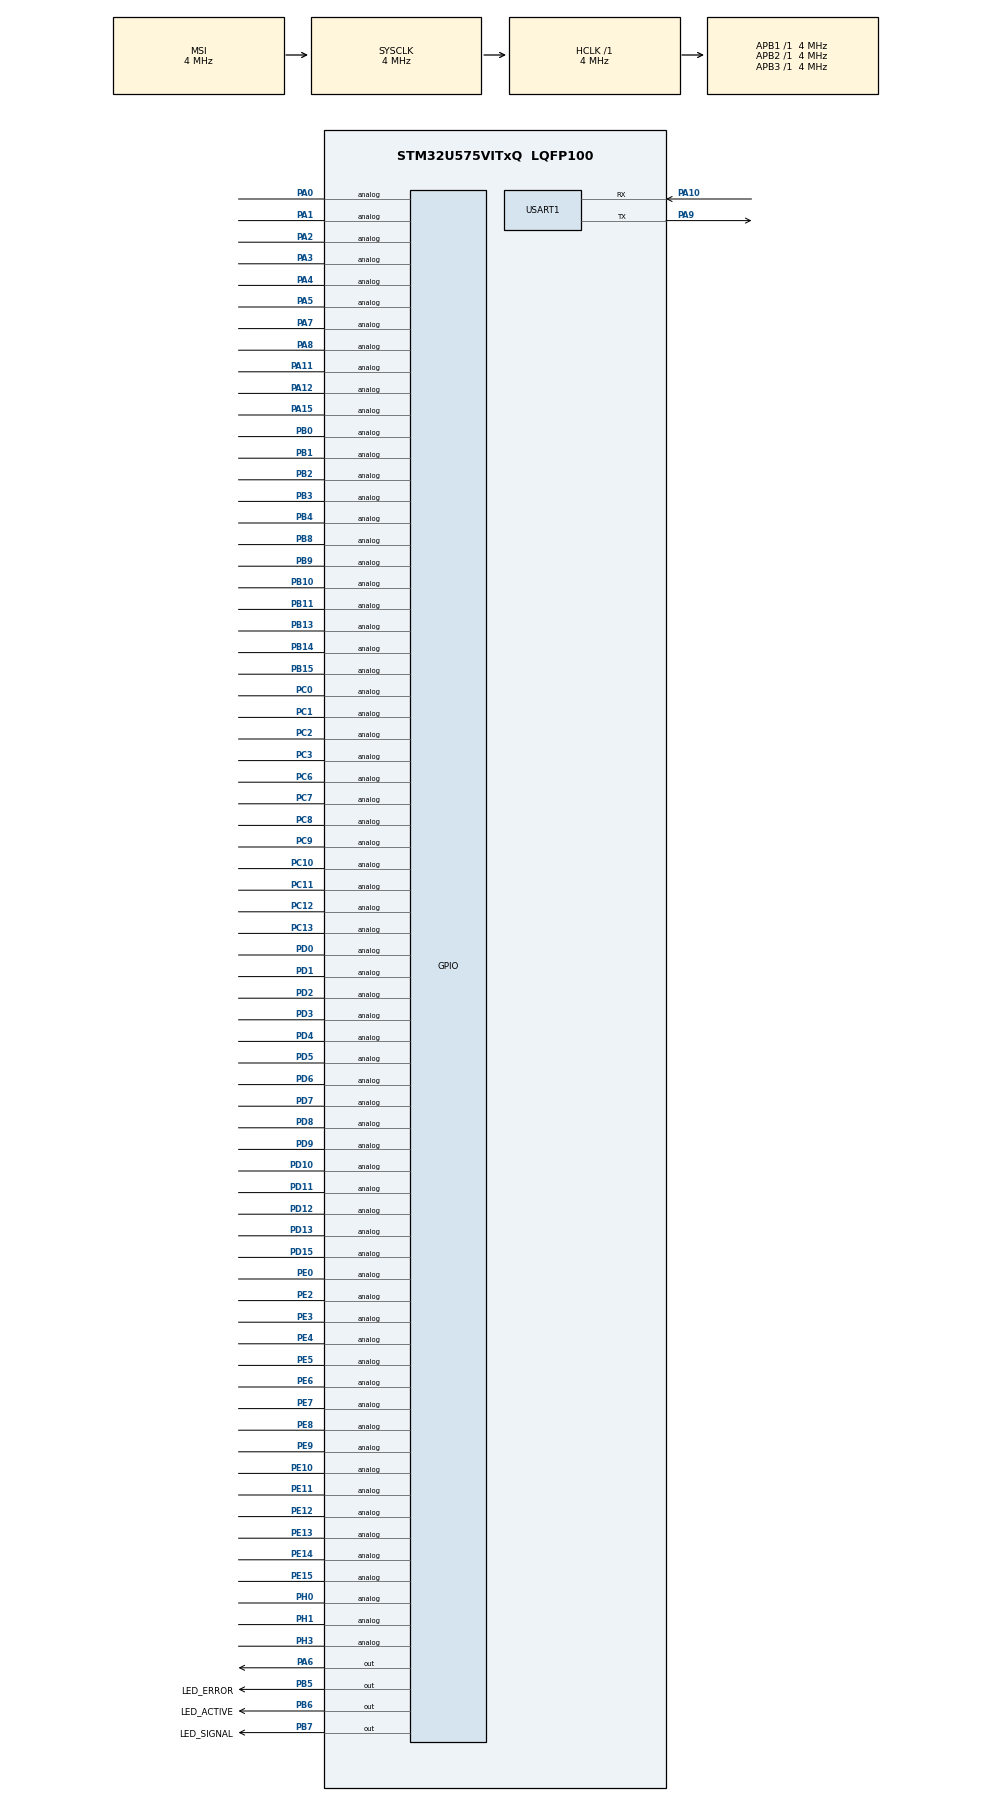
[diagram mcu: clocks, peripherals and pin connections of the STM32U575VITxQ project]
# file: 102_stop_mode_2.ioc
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CORTEX_M33_NS.userName=CORTEX_M33
Mcu.Family=STM32U5
Mcu.Name=STM32U575VITxQ
Mcu.Package=LQFP100
NVIC.PriorityGroup=NVIC_PRIORITYGROUP_4
NVIC.RTC_IRQn=true\:0\:0\:false\:false\:true\:true\:true\:true
PA0.Signal=GPIO_Analog
PA1.Signal=GPIO_Analog
PA10.Mode=Asynchronous
PA10.Signal=USART1_RX
PA11.Signal=GPIO_Analog
PA12.Signal=GPIO_Analog
PA13\ (JTMS/SWDIO).Mode=Serial_Wire
PA13\ (JTMS/SWDIO).Signal=DEBUG_JTMS-SWDIO
PA14\ (JTCK/SWCLK).Mode=Serial_Wire
PA14\ (JTCK/SWCLK).Signal=DEBUG_JTCK-SWCLK
PA15\ (JTDI).Signal=GPIO_Analog
PA2.Signal=GPIO_Analog
PA3.Signal=GPIO_Analog
PA4.Signal=GPIO_Analog
PA5.Signal=GPIO_Analog
PA6.Signal=GPIO_Output
PA7.Signal=GPIO_Analog
PA8.Signal=GPIO_Analog
PA9.Mode=Asynchronous
PA9.Signal=USART1_TX
PB0.Signal=GPIO_Analog
PB1.Signal=GPIO_Analog
PB10.Signal=GPIO_Analog
PB11.Signal=GPIO_Analog
PB13.Signal=GPIO_Analog
PB14.Signal=GPIO_Analog
PB15.Signal=GPIO_Analog
PB2.Signal=GPIO_Analog
PB3\ (JTDO/TRACESWO).Signal=GPIO_Analog
PB4\ (NJTRST).Signal=GPIO_Analog
PB5.GPIO_Label=LED_ERROR
PB5.Signal=GPIO_Output
PB6.GPIO_Label=LED_ACTIVE
PB6.Signal=GPIO_Output
PB7.GPIO_Label=LED_SIGNAL
PB7.Signal=GPIO_Output
PB8.Signal=GPIO_Analog
PB9.Signal=GPIO_Analog
PC0.Signal=GPIO_Analog
PC1.Signal=GPIO_Analog
PC10.Signal=GPIO_Analog
PC11.Signal=GPIO_Analog
PC12.Signal=GPIO_Analog
PC13.Signal=GPIO_Analog
PC14-OSC32_IN\ (PC14).Mode=LSE-External-Oscillator
PC14-OSC32_IN\ (PC14).Signal=RCC_OSC32_IN
PC15-OSC32_OUT\ (PC15).Mode=LSE-External-Oscillator
PC15-OSC32_OUT\ (PC15).Signal=RCC_OSC32_OUT
PC2.Signal=GPIO_Analog
PC3.Signal=GPIO_Analog
PC6.Signal=GPIO_Analog
PC7.Signal=GPIO_Analog
PC8.Signal=GPIO_Analog
PC9.Signal=GPIO_Analog
PD0.Signal=GPIO_Analog
PD1.Signal=GPIO_Analog
PD10.Signal=GPIO_Analog
PD11.Signal=GPIO_Analog
PD12.Signal=GPIO_Analog
PD13.Signal=GPIO_Analog
PD14.Signal=S_LPTIM3_CH1
PD15.Signal=GPIO_Analog
PD2.Signal=GPIO_Analog
PD3.Signal=GPIO_Analog
PD4.Signal=GPIO_Analog
PD5.Signal=GPIO_Analog
PD6.Signal=GPIO_Analog
PD7.Signal=GPIO_Analog
PD8.Signal=GPIO_Analog
PD9.Signal=GPIO_Analog
PE0.Signal=GPIO_Analog
PE10.Signal=GPIO_Analog
PE11.Signal=GPIO_Analog
PE12.Signal=GPIO_Analog
PE13.Signal=GPIO_Analog
PE14.Signal=GPIO_Analog
PE15.Signal=GPIO_Analog
PE2.Signal=GPIO_Analog
PE3.Signal=GPIO_Analog
PE4.Signal=GPIO_Analog
PE5.Signal=GPIO_Analog
PE6.Signal=GPIO_Analog
PE7.Signal=GPIO_Analog
PE8.Signal=GPIO_Analog
PE9.Signal=GPIO_Analog
PH0-OSC_IN\ (PH0).Signal=GPIO_Analog
PH1-OSC_OUT\ (PH1).Signal=GPIO_Analog
PH3-BOOT0.Signal=GPIO_Analog
PWR.PowerMode=PWR_SMPS_SUPPLY
PWR.RAM1Page1PowerDownInStopMode=__NULL
PWR.RAM1Page2PowerDownInStopMode=__NULL
PWR.RAM1Page3PowerDownInStopMode=__NULL
PWR.RAM2Page1PowerDownInStopMode=__NULL
PWR.RAM2Page2PowerDownInStopMode=__NULL
PWR.RAM3Page1PowerDownInStopMode=__NULL
PWR.RAM3Page2PowerDownInStopMode=__NULL
PWR.RAM3Page3PowerDownInStopMode=__NULL
PWR.RAM3Page4PowerDownInStopMode=__NULL
PWR.RAM3Page5PowerDownInStopMode=__NULL
PWR.RAM3Page6PowerDownInStopMode=__NULL
PWR.RAM3Page7PowerDownInStopMode=__NULL
PWR.RAM3Page8PowerDownInStopMode=__NULL
PWR.SRAM4PowerDownInStopMode=__NULL
ProjectManager.HeapSize=0x200
ProjectManager.StackSize=0x400
ProjectManager.TargetToolchain=STM32CubeIDE
RCC.ADCFreq_Value=16000000
RCC.AHBFreq_Value=4000000
RCC.APB1Freq_Value=4000000
RCC.APB1TimFreq_Value=4000000
RCC.APB2Freq_Value=4000000
RCC.APB2TimFreq_Value=4000000
RCC.APB3Freq_Value=4000000
RCC.CortexFreq_Value=4000000
RCC.EPOD_VALUE=4000000
RCC.HCLKFreq_Value=4000000
RCC.HSE_VALUE=16000000
RCC.HSI48_VALUE=48000000
RCC.HSI_VALUE=16000000
RCC.LPTIM3CLockSelectionVirtual=RCC_LPTIM34CLKSOURCE_LSE
RCC.LSIDIV_VALUE=32000
RCC.MSI_VALUE=4000000
RCC.RTCClockSelection=RCC_RTCCLKSOURCE_LSE
RCC.SYSCLKFreq_VALUE=4000000
RCC.USBFreq_Value=48000000
RCC.VCOOutputFreq_Value=516000000
RCC.VDD_VALUE=3
RTC.WakeUpClock-WakeUp=RTC_WAKEUPCLOCK_CK_SPRE_16BITS
RTC.WakeUpCounter-WakeUp=0
SH.S_LPTIM3_CH1.0=LPTIM3_CH1
USART1.VirtualMode-Asynchronous=VM_ASYNC
VP_ICACHE_VS_ICACHE.Mode=DirectMappedCache
VP_LPBAMQUEUE_VS_QUEUE.Mode=QUEUEMODE
VP_LPBAM_VS_SIG1.Mode=SmartRun
VP_LPBAM_VS_SIG4.Mode=LPDMA1
VP_MEMORYMAP_VS_MEMORYMAP.Mode=CurAppReg
VP_PWR_VS_DBSignals.Mode=DisableDeadBatterySignals
VP_PWR_VS_LPOM.Mode=PowerOptimisation
VP_PWR_VS_SECSignals.Mode=Security/Privilege
VP_RTC_VS_RTC_Activate.Mode=RTC_Enabled
VP_RTC_VS_RTC_WakeUp_intern.Mode=WakeUp
board=custom

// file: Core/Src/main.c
/* USER CODE BEGIN Header */
/**
  ******************************************************************************
  * @file           : main.c
  * @brief          : Main program body
  ******************************************************************************
  * @attention
  *
  * Copyright (c) 2024 STMicroelectronics.
  * All rights reserved.
  *
  * This software is licensed under terms that can be found in the LICENSE file
  * in the root directory of this software component.
  * If no LICENSE file comes with this software, it is provided AS-IS.
  *
  ******************************************************************************
  */
/* USER CODE END Header */
#include "main.h"

/* USER CODE BEGIN Includes */
#include "fm_main.h"
/* USER CODE END Includes */

RTC_HandleTypeDef hrtc;

UART_HandleTypeDef huart1;

void SystemClock_Config(void);
static void SystemPower_Config(void);
static void MX_GPIO_Init(void);
static void MX_ICACHE_Init(void);
static void MX_USART1_UART_Init(void);
static void MX_RTC_Init(void);

int main(void)
{

  /* MCU Configuration--------------------------------------------------------*/

  /* Reset of all peripherals, Initializes the Flash interface and the Systick. */
  HAL_Init();

  /* Configure the System Power */
  SystemPower_Config();

  /* Configure the system clock */
  SystemClock_Config();

  /* Initialize all configured peripherals */
  MX_GPIO_Init();
  MX_ICACHE_Init();
  MX_USART1_UART_Init();
  MX_RTC_Init();

  /* Infinite loop */
  /* USER CODE BEGIN WHILE */
  while (1)
  {
	  FM_MAIN_Main();

    /* USER CODE END WHILE */

  }
}

void SystemClock_Config(void)
{
  RCC_OscInitTypeDef RCC_OscInitStruct = {0};
  RCC_ClkInitTypeDef RCC_ClkInitStruct = {0};

  /** Configure the main internal regulator output voltage
  */
  if (HAL_PWREx_ControlVoltageScaling(PWR_REGULATOR_VOLTAGE_SCALE4) != HAL_OK)
  {
    Error_Handler();
  }

  /** Configure LSE Drive Capability
  */
  HAL_PWR_EnableBkUpAccess();
  __HAL_RCC_LSEDRIVE_CONFIG(RCC_LSEDRIVE_LOW);

  /** Initializes the CPU, AHB and APB buses clocks
  */
  RCC_OscInitStruct.OscillatorType = RCC_OSCILLATORTYPE_LSE|RCC_OSCILLATORTYPE_MSI;
  RCC_OscInitStruct.LSEState = RCC_LSE_ON;
  RCC_OscInitStruct.MSIState = RCC_MSI_ON;
  RCC_OscInitStruct.MSICalibrationValue = RCC_MSICALIBRATION_DEFAULT;
  RCC_OscInitStruct.MSIClockRange = RCC_MSIRANGE_4;
  RCC_OscInitStruct.PLL.PLLState = RCC_PLL_NONE;
  if (HAL_RCC_OscConfig(&RCC_OscInitStruct) != HAL_OK)
  {
    Error_Handler();
  }

  /** Initializes the CPU, AHB and APB buses clocks
  */
  RCC_ClkInitStruct.ClockType = RCC_CLOCKTYPE_HCLK|RCC_CLOCKTYPE_SYSCLK
                              |RCC_CLOCKTYPE_PCLK1|RCC_CLOCKTYPE_PCLK2
                              |RCC_CLOCKTYPE_PCLK3;
  RCC_ClkInitStruct.SYSCLKSource = RCC_SYSCLKSOURCE_MSI;
  RCC_ClkInitStruct.AHBCLKDivider = RCC_SYSCLK_DIV1;
  RCC_ClkInitStruct.APB1CLKDivider = RCC_HCLK_DIV1;
  RCC_ClkInitStruct.APB2CLKDivider = RCC_HCLK_DIV1;
  RCC_ClkInitStruct.APB3CLKDivider = RCC_HCLK_DIV1;

  if (HAL_RCC_ClockConfig(&RCC_ClkInitStruct, FLASH_LATENCY_0) != HAL_OK)
  {
    Error_Handler();
  }
}

/**
  * @brief Power Configuration
  * @retval None
  */
static void SystemPower_Config(void)
{

  /*
   * Disable the internal Pull-Up in Dead Battery pins of UCPD peripheral
   */
  HAL_PWREx_DisableUCPDDeadBattery();

  /*
   * Switch to SMPS regulator instead of LDO
   */
  if (HAL_PWREx_ConfigSupply(PWR_SMPS_SUPPLY) != HAL_OK)
  {
    Error_Handler();
  }
}

static void MX_ICACHE_Init(void)
{

  /** Enable instruction cache in 1-way (direct mapped cache)
  */
  if (HAL_ICACHE_ConfigAssociativityMode(ICACHE_1WAY) != HAL_OK)
  {
    Error_Handler();
  }
  if (HAL_ICACHE_Enable() != HAL_OK)
  {
    Error_Handler();
  }

}

static void MX_RTC_Init(void)
{

  RTC_PrivilegeStateTypeDef privilegeState = {0};

  /** Initialize RTC Only
  */
  hrtc.Instance = RTC;
  hrtc.Init.HourFormat = RTC_HOURFORMAT_24;
  hrtc.Init.AsynchPrediv = 127;
  hrtc.Init.SynchPrediv = 255;
  hrtc.Init.OutPut = RTC_OUTPUT_DISABLE;
  hrtc.Init.OutPutRemap = RTC_OUTPUT_REMAP_NONE;
  hrtc.Init.OutPutPolarity = RTC_OUTPUT_POLARITY_HIGH;
  hrtc.Init.OutPutType = RTC_OUTPUT_TYPE_OPENDRAIN;
  hrtc.Init.OutPutPullUp = RTC_OUTPUT_PULLUP_NONE;
  hrtc.Init.BinMode = RTC_BINARY_NONE;
  if (HAL_RTC_Init(&hrtc) != HAL_OK)
  {
    Error_Handler();
  }
  privilegeState.rtcPrivilegeFull = RTC_PRIVILEGE_FULL_NO;
  privilegeState.backupRegisterPrivZone = RTC_PRIVILEGE_BKUP_ZONE_NONE;
  privilegeState.backupRegisterStartZone2 = RTC_BKP_DR0;
  privilegeState.backupRegisterStartZone3 = RTC_BKP_DR0;
  if (HAL_RTCEx_PrivilegeModeSet(&hrtc, &privilegeState) != HAL_OK)
  {
    Error_Handler();
  }

  /** Enable the WakeUp
  */
  if (HAL_RTCEx_SetWakeUpTimer_IT(&hrtc, 0, RTC_WAKEUPCLOCK_CK_SPRE_16BITS, 0) != HAL_OK)
  {
    Error_Handler();
  }

}

static void MX_USART1_UART_Init(void)
{

  huart1.Instance = USART1;
  huart1.Init.BaudRate = 115200;
  huart1.Init.WordLength = UART_WORDLENGTH_8B;
  huart1.Init.StopBits = UART_STOPBITS_1;
  huart1.Init.Parity = UART_PARITY_NONE;
  huart1.Init.Mode = UART_MODE_TX_RX;
  huart1.Init.HwFlowCtl = UART_HWCONTROL_NONE;
  huart1.Init.OverSampling = UART_OVERSAMPLING_16;
  huart1.Init.OneBitSampling = UART_ONE_BIT_SAMPLE_DISABLE;
  huart1.Init.ClockPrescaler = UART_PRESCALER_DIV1;
  huart1.AdvancedInit.AdvFeatureInit = UART_ADVFEATURE_NO_INIT;
  if (HAL_UART_Init(&huart1) != HAL_OK)
  {
    Error_Handler();
  }
  if (HAL_UARTEx_SetTxFifoThreshold(&huart1, UART_TXFIFO_THRESHOLD_1_8) != HAL_OK)
  {
    Error_Handler();
  }
  if (HAL_UARTEx_SetRxFifoThreshold(&huart1, UART_RXFIFO_THRESHOLD_1_8) != HAL_OK)
  {
    Error_Handler();
  }
  if (HAL_UARTEx_DisableFifoMode(&huart1) != HAL_OK)
  {
    Error_Handler();
  }

}

static void MX_GPIO_Init(void)
{
  GPIO_InitTypeDef GPIO_InitStruct = {0};

  /* GPIO Ports Clock Enable */
  __HAL_RCC_GPIOE_CLK_ENABLE();
  __HAL_RCC_GPIOC_CLK_ENABLE();
  __HAL_RCC_GPIOH_CLK_ENABLE();
  __HAL_RCC_GPIOA_CLK_ENABLE();
  __HAL_RCC_GPIOB_CLK_ENABLE();
  __HAL_RCC_GPIOD_CLK_ENABLE();

  /*Configure GPIO pin Output Level */
  HAL_GPIO_WritePin(GPIOA, GPIO_PIN_6, GPIO_PIN_RESET);

  /*Configure GPIO pin Output Level */
  HAL_GPIO_WritePin(GPIOB, LED_ERROR_Pin|LED_ACTIVE_Pin|LED_SIGNAL_Pin, GPIO_PIN_RESET);

  /*Configure GPIO pins : PE2 PE3 PE4 PE5
                           PE6 PE7 PE8 PE9
                           PE10 PE11 PE12 PE13
                           PE14 PE15 PE0 */
  GPIO_InitStruct.Pin = GPIO_PIN_2|GPIO_PIN_3|GPIO_PIN_4|GPIO_PIN_5
                          |GPIO_PIN_6|GPIO_PIN_7|GPIO_PIN_8|GPIO_PIN_9
                          |GPIO_PIN_10|GPIO_PIN_11|GPIO_PIN_12|GPIO_PIN_13
                          |GPIO_PIN_14|GPIO_PIN_15|GPIO_PIN_0;
  GPIO_InitStruct.Mode = GPIO_MODE_ANALOG;
  GPIO_InitStruct.Pull = GPIO_NOPULL;
  HAL_GPIO_Init(GPIOE, &GPIO_InitStruct);

  /*Configure GPIO pins : PC13 PC0 PC1 PC2
                           PC3 PC6 PC7 PC8
                           PC9 PC10 PC11 PC12 */
  GPIO_InitStruct.Pin = GPIO_PIN_13|GPIO_PIN_0|GPIO_PIN_1|GPIO_PIN_2
                          |GPIO_PIN_3|GPIO_PIN_6|GPIO_PIN_7|GPIO_PIN_8
                          |GPIO_PIN_9|GPIO_PIN_10|GPIO_PIN_11|GPIO_PIN_12;
  GPIO_InitStruct.Mode = GPIO_MODE_ANALOG;
  GPIO_InitStruct.Pull = GPIO_NOPULL;
  HAL_GPIO_Init(GPIOC, &GPIO_InitStruct);

  /*Configure GPIO pins : PH0 PH1 PH3 */
  GPIO_InitStruct.Pin = GPIO_PIN_0|GPIO_PIN_1|GPIO_PIN_3;
  GPIO_InitStruct.Mode = GPIO_MODE_ANALOG;
  GPIO_InitStruct.Pull = GPIO_NOPULL;
  HAL_GPIO_Init(GPIOH, &GPIO_InitStruct);

  /*Configure GPIO pins : PA0 PA1 PA2 PA3
                           PA4 PA5 PA7 PA8
                           PA11 PA12 PA15 */
  GPIO_InitStruct.Pin = GPIO_PIN_0|GPIO_PIN_1|GPIO_PIN_2|GPIO_PIN_3
                          |GPIO_PIN_4|GPIO_PIN_5|GPIO_PIN_7|GPIO_PIN_8
                          |GPIO_PIN_11|GPIO_PIN_12|GPIO_PIN_15;
  GPIO_InitStruct.Mode = GPIO_MODE_ANALOG;
  GPIO_InitStruct.Pull = GPIO_NOPULL;
  HAL_GPIO_Init(GPIOA, &GPIO_InitStruct);

  /*Configure GPIO pin : PA6 */
  GPIO_InitStruct.Pin = GPIO_PIN_6;
  GPIO_InitStruct.Mode = GPIO_MODE_OUTPUT_PP;
  GPIO_InitStruct.Pull = GPIO_NOPULL;
  GPIO_InitStruct.Speed = GPIO_SPEED_FREQ_LOW;
  HAL_GPIO_Init(GPIOA, &GPIO_InitStruct);

  /*Configure GPIO pins : PB0 PB1 PB2 PB10
                           PB11 PB13 PB14 PB15
                           PB3 PB4 PB8 PB9 */
  GPIO_InitStruct.Pin = GPIO_PIN_0|GPIO_PIN_1|GPIO_PIN_2|GPIO_PIN_10
                          |GPIO_PIN_11|GPIO_PIN_13|GPIO_PIN_14|GPIO_PIN_15
                          |GPIO_PIN_3|GPIO_PIN_4|GPIO_PIN_8|GPIO_PIN_9;
  GPIO_InitStruct.Mode = GPIO_MODE_ANALOG;
  GPIO_InitStruct.Pull = GPIO_NOPULL;
  HAL_GPIO_Init(GPIOB, &GPIO_InitStruct);

  /*Configure GPIO pins : PD8 PD9 PD10 PD11
                           PD12 PD13 PD15 PD0
                           PD1 PD2 PD3 PD4
                           PD5 PD6 PD7 */
  GPIO_InitStruct.Pin = GPIO_PIN_8|GPIO_PIN_9|GPIO_PIN_10|GPIO_PIN_11
                          |GPIO_PIN_12|GPIO_PIN_13|GPIO_PIN_15|GPIO_PIN_0
                          |GPIO_PIN_1|GPIO_PIN_2|GPIO_PIN_3|GPIO_PIN_4
                          |GPIO_PIN_5|GPIO_PIN_6|GPIO_PIN_7;
  GPIO_InitStruct.Mode = GPIO_MODE_ANALOG;
  GPIO_InitStruct.Pull = GPIO_NOPULL;
  HAL_GPIO_Init(GPIOD, &GPIO_InitStruct);

  /*Configure GPIO pin : PD14 */
  GPIO_InitStruct.Pin = GPIO_PIN_14;
  GPIO_InitStruct.Mode = GPIO_MODE_AF_PP;
  GPIO_InitStruct.Pull = GPIO_NOPULL;
  GPIO_InitStruct.Speed = GPIO_SPEED_FREQ_LOW;
  GPIO_InitStruct.Alternate = GPIO_AF14_LPTIM3;
  HAL_GPIO_Init(GPIOD, &GPIO_InitStruct);

  /*Configure GPIO pins : LED_ERROR_Pin LED_ACTIVE_Pin LED_SIGNAL_Pin */
  GPIO_InitStruct.Pin = LED_ERROR_Pin|LED_ACTIVE_Pin|LED_SIGNAL_Pin;
  GPIO_InitStruct.Mode = GPIO_MODE_OUTPUT_PP;
  GPIO_InitStruct.Pull = GPIO_NOPULL;
  GPIO_InitStruct.Speed = GPIO_SPEED_FREQ_LOW;
  HAL_GPIO_Init(GPIOB, &GPIO_InitStruct);

}

void Error_Handler(void)
{
  __disable_irq();
  while (1)
  {
  }
}
